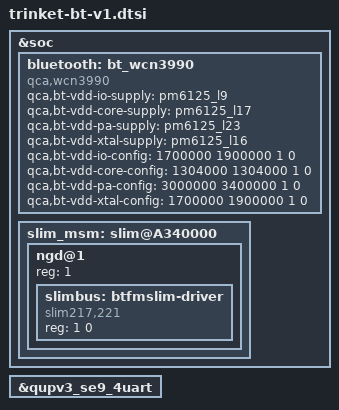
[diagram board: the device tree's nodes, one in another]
#include <dt-bindings/soc/qcom,ipcc.h>

&soc {
  bluetooth: bt_wcn3990 {
    compatible = "qca,wcn3990";

    qca,bt-vdd-io-supply = <&pm6125_l9>;
    qca,bt-vdd-core-supply = <&pm6125_l17>;
    qca,bt-vdd-pa-supply = <&pm6125_l23>;
    qca,bt-vdd-xtal-supply = <&pm6125_l16>;

    qca,bt-vdd-io-config = <1700000 1900000 1 0>;
    qca,bt-vdd-core-config = <1304000 1304000 1 0>;
    qca,bt-vdd-pa-config = <3000000 3400000 1 0>;
    qca,bt-vdd-xtal-config = <1700000 1900000 1 0>;
  };

  slim_msm: slim@A340000  {
    status =  "ok";
    ngd@1 {
      reg = <1>;
      #address-cells = <1>;
      #size-cells = <1>;
      //slimbus child nodes
      slimbus: btfmslim-driver {
      compatible = "slim217,221";
      reg = <1 0>;
      };
    };
  };
};

&qupv3_se9_4uart {
  status = "ok";
};
